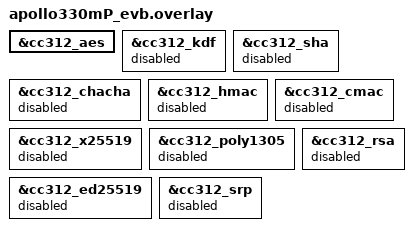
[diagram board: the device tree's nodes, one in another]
/*
 * Copyright (c) 2026 Ambiq Micro, Inc.
 * SPDX-License-Identifier: Apache-2.0
 */

/*
 * Root/HUK CMAC-KDF is am_hal_cc312_root_kdf_cmac() on the AES engine (RKEK),
 * not the Zephyr cc312_kdf node (that is HKDF / USER IKM). Enable AES for the
 * crypto driver + arbiter; leave other CC312 siblings off (shared IRQ).
 */
&cc312_aes {
	status = "okay";
};

&cc312_kdf {
	status = "disabled";
};

&cc312_sha {
	status = "disabled";
};

&cc312_chacha {
	status = "disabled";
};

&cc312_hmac {
	status = "disabled";
};

&cc312_cmac {
	status = "disabled";
};

&cc312_x25519 {
	status = "disabled";
};

&cc312_poly1305 {
	status = "disabled";
};

&cc312_ed25519 {
	status = "disabled";
};

&cc312_rsa {
	status = "disabled";
};

&cc312_srp {
	status = "disabled";
};
